# PIC32MK0128MCA032 register map
Vendor: Microchip
Registers are 32-bit, read-write, reset 0x0 unless marked. A register's access mark holds for its fields unless they carry their own. Addresses are absolute, and some are shared; only a register's first bit layout is shown; [hi:lo] are bit positions; {n}, {i} and the like mark numbered series; 'fields as' and 'values as' point back to an identical list.

## ADCHS
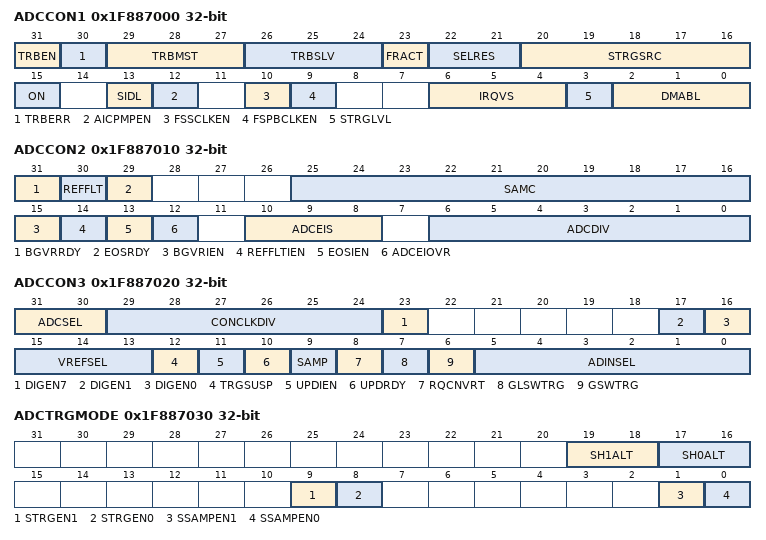
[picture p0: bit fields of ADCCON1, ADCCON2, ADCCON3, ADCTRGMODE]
0x1F887000 ADCCON1 reset not defined — (power-on value 00000110000000000-00-00--0000xxx)
  [31] TRBEN, [30] TRBERR ro, [29:27] TRBMST, [26:24] TRBSLV, [23] FRACT, [22:21] SELRES, [20:16] STRGSRC, [15] ON, [13] SIDL, [12] AICPMPEN, [10] FSSCLKEN, [9] FSPBCLKEN, [6:4] IRQVS, [3] STRGLVL, [2:0] DMABL
0x1F887010 ADCCON2
  [31] BGVRRDY ro, [30] REFFLT ro, [29] EOSRDY ro, [25:16] SAMC, [15] BGVRIEN, [14] REFFLTIEN, [13] EOSIEN, [12] ADCEIOVR, [10:8] ADCEIS, [6:0] ADCDIV
0x1F887020 ADCCON3
  [31:30] ADCSEL, [29:24] CONCLKDIV, [23] DIGEN7 ro, [17] DIGEN1 ro, [16] DIGEN0 ro, [15:13] VREFSEL, [12] TRGSUSP, [11] UPDIEN, [10] UPDRDY, [9] SAMP, [8] RQCNVRT, [7] GLSWTRG, [6] GSWTRG, [5:0] ADINSEL
0x1F887030 ADCTRGMODE
  [19:18] SH1ALT, [17:16] SH0ALT, [9] STRGEN1, [8] STRGEN0, [1] SSAMPEN1, [0] SSAMPEN0
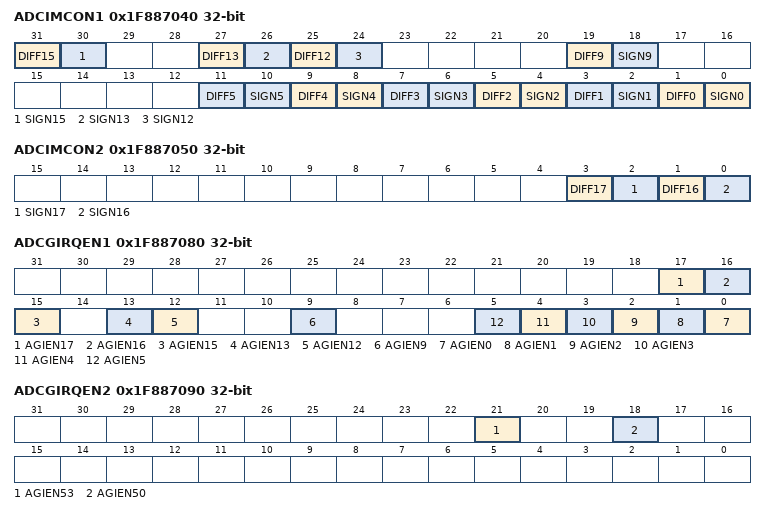
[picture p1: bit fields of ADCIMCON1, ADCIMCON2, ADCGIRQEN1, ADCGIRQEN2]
0x1F887040 ADCIMCON1
  [31] DIFF15, [30] SIGN15, [27] DIFF13, [26] SIGN13, [25] DIFF12, [24] SIGN12, [19] DIFF9, [18] SIGN9, [2n+1] DIFF{n} (n=0..5), [2n] SIGN{n} (n=0..5)
0x1F887050 ADCIMCON2
  [3] DIFF17, [2] SIGN17, [1] DIFF16, [0] SIGN16
0x1F887080 ADCGIRQEN1
  [17] AGIEN17, [16] AGIEN16, [15] AGIEN15, [13] AGIEN13, [12] AGIEN12, [9] AGIEN9, [n] AGIEN{n} (n=0..5)
0x1F887090 ADCGIRQEN2
  [21] AGIEN53, [18] AGIEN50
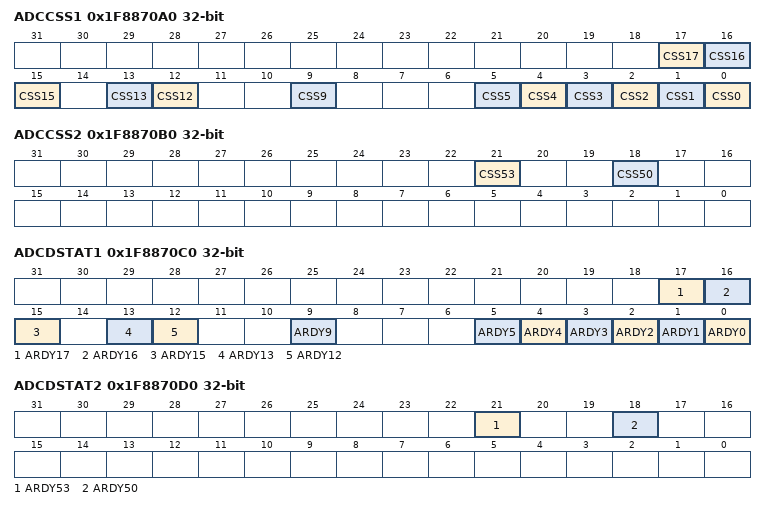
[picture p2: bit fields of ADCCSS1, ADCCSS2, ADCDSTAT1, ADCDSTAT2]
0x1F8870A0 ADCCSS1
  [17] CSS17, [16] CSS16, [15] CSS15, [13] CSS13, [12] CSS12, [9] CSS9, [n] CSS{n} (n=0..5)
0x1F8870B0 ADCCSS2
  [21] CSS53, [18] CSS50
0x1F8870C0 ADCDSTAT1 ro
  [17] ARDY17, [16] ARDY16, [15] ARDY15, [13] ARDY13, [12] ARDY12, [9] ARDY9, [n] ARDY{n} (n=0..5)
0x1F8870D0 ADCDSTAT2 ro
  [21] ARDY53, [18] ARDY50
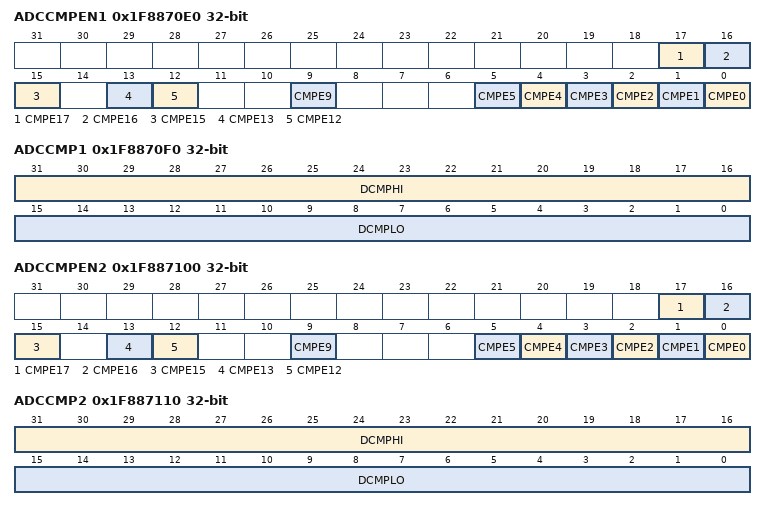
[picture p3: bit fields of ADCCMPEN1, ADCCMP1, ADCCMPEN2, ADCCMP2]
0x1F8870E0 ADCCMPEN1
  [17] CMPE17, [16] CMPE16, [15] CMPE15, [13] CMPE13, [12] CMPE12, [9] CMPE9, [n] CMPE{n} (n=0..5)
0x1F8870F0 ADCCMP1
  [31:16] DCMPHI, [15:0] DCMPLO
0x1F887100 ADCCMPEN2
  fields as ADCCMPEN1
0x1F887110 ADCCMP2
  [31:16] DCMPHI, [15:0] DCMPLO
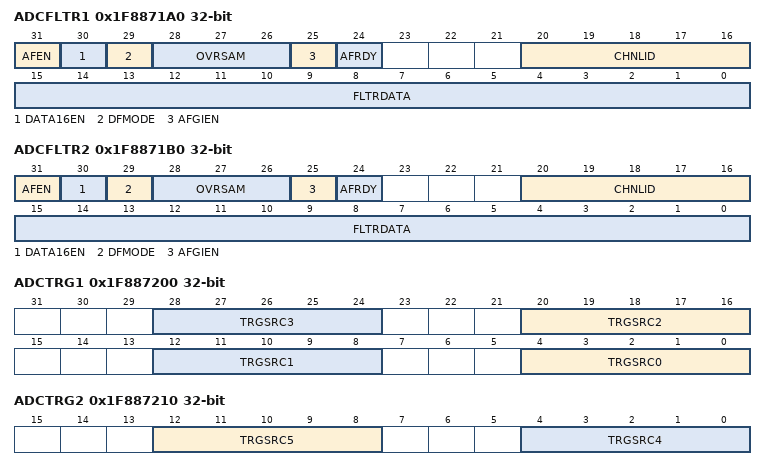
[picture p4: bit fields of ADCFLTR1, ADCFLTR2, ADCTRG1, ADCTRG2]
0x1F8871A0 ADCFLTR1
  [31] AFEN, [30] DATA16EN, [29] DFMODE, [28:26] OVRSAM, [25] AFGIEN, [24] AFRDY ro, [20:16] CHNLID, [15:0] FLTRDATA ro
0x1F8871B0 ADCFLTR2
  fields as ADCFLTR1
0x1F887200 ADCTRG1
  [8n+4:8n] TRGSRC{n} (n=0..3)
0x1F887210 ADCTRG2
  [12:8] TRGSRC5, [4:0] TRGSRC4
0x1F887220 ADCTRG3
  [12:8] TRGSRC9
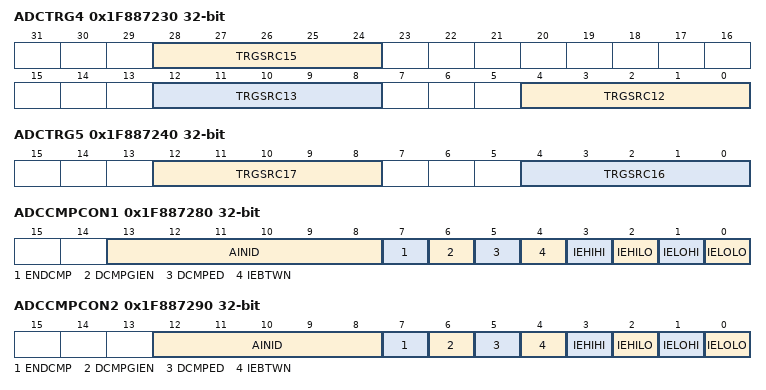
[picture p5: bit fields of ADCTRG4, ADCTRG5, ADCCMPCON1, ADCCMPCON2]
0x1F887230 ADCTRG4
  [28:24] TRGSRC15, [12:8] TRGSRC13, [4:0] TRGSRC12
0x1F887240 ADCTRG5
  [12:8] TRGSRC17, [4:0] TRGSRC16
0x1F887280 ADCCMPCON1
  [13:8] AINID ro, [7] ENDCMP, [6] DCMPGIEN, [5] DCMPED ro, [4] IEBTWN, [3] IEHIHI, [2] IEHILO, [1] IELOHI, [0] IELOLO
0x1F887290 ADCCMPCON2
  [12:8] AINID ro, [7] ENDCMP, [6] DCMPGIEN, [5] DCMPED ro, [4] IEBTWN, [3] IEHIHI, [2] IEHILO, [1] IELOHI, [0] IELOLO
0x1F887300 ADCBASE
  [15:0] ADCBASE
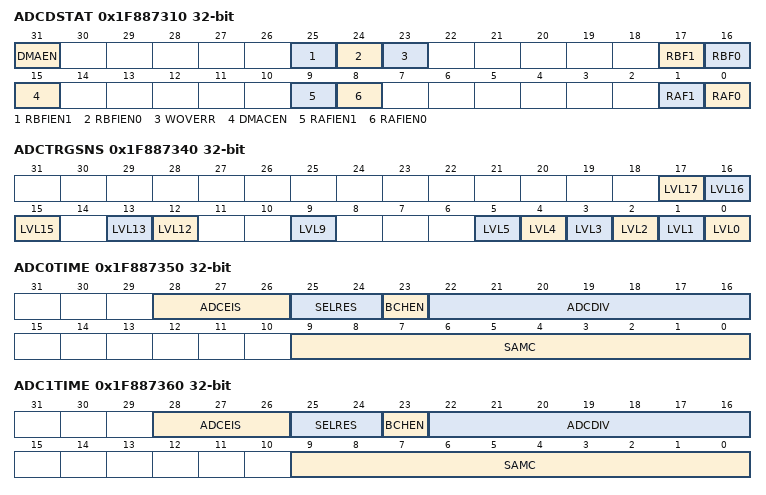
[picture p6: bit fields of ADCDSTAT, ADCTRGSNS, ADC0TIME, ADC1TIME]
0x1F887310 ADCDSTAT
  [31] DMAEN, [25] RBFIEN1, [24] RBFIEN0, [23] WOVERR ro, [17] RBF1 ro, [16] RBF0 ro, [15] DMACEN, [9] RAFIEN1, [8] RAFIEN0, [1] RAF1 ro, [0] RAF0 ro
0x1F887320 ADCCNTB
0x1F887330 ADCDMAB
0x1F887340 ADCTRGSNS
  [17] LVL17, [16] LVL16, [15] LVL15, [13] LVL13, [12] LVL12, [9] LVL9, [n] LVL{n} (n=0..5)
0x1F887350 ADC0TIME reset not defined — (power-on value ---00000x0000000------0000000000)
  [28:26] ADCEIS, [25:24] SELRES, [23] BCHEN, [22:16] ADCDIV, [9:0] SAMC
0x1F887360 ADC1TIME reset not defined — (power-on value ---00000x0000000------0000000000)
  fields as ADC0TIME
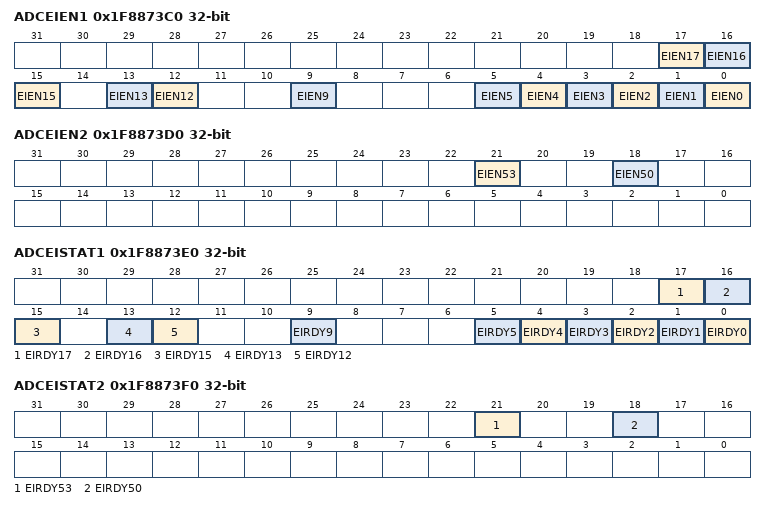
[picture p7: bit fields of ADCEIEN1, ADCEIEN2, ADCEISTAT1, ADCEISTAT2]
0x1F8873C0 ADCEIEN1
  [17] EIEN17, [16] EIEN16, [15] EIEN15, [13] EIEN13, [12] EIEN12, [9] EIEN9, [n] EIEN{n} (n=0..5)
0x1F8873D0 ADCEIEN2
  [21] EIEN53, [18] EIEN50
0x1F8873E0 ADCEISTAT1 ro
  [17] EIRDY17, [16] EIRDY16, [15] EIRDY15, [13] EIRDY13, [12] EIRDY12, [9] EIRDY9, [n] EIRDY{n} (n=0..5)
0x1F8873F0 ADCEISTAT2 reset not defined — (power-on value ----------x--x------------------)
  [21] EIRDY53, [18] EIRDY50
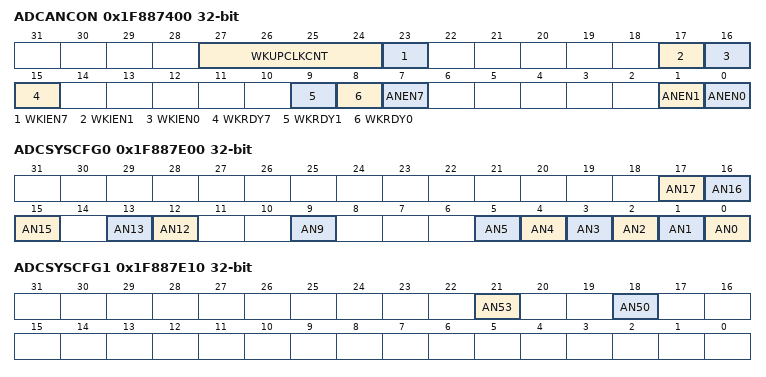
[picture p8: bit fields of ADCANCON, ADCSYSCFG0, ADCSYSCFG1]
0x1F887400 ADCANCON
  [27:24] WKUPCLKCNT, [23] WKIEN7, [17] WKIEN1, [16] WKIEN0, [15] WKRDY7 ro, [9] WKRDY1 ro, [8] WKRDY0 ro, [7] ANEN7, [1] ANEN1, [0] ANEN0
{0x1F887600+0x10*i} ADCDATA{i} (i=0..5)
  [31:0] DATA
0x1F887690 ADCDATA9
  [31:0] DATA
0x1F8876C0 ADCDATA12
  [31:0] DATA
0x1F8876D0 ADCDATA13
  [31:0] DATA
{0x1F887600+0x10*i} ADCDATA{i} (i=15..17)
  [31:0] DATA
0x1F887920 ADCDATA50
  [31:0] DATA
0x1F887950 ADCDATA53
  [31:0] DATA
0x1F887D00 ADC0CFG
  [31:0] ADCCFG
0x1F887D10 ADC1CFG
  [31:0] ADCCFG
0x1F887D70 ADC7CFG
  [31:0] ADCCFG
0x1F887E00 ADCSYSCFG0 ro
  [17] AN17, [16] AN16, [15] AN15, [13] AN13, [12] AN12, [9] AN9, [n] AN{n} (n=0..5)
0x1F887E10 ADCSYSCFG1 ro
  [21] AN53, [18] AN50
